# CEC1702 register map
Vendor: Microchip Technology; Series: CEC1702Q; File version: 0
CPU: CM4 r1p0, little endian, MPU, FPU, 3 interrupt priority bits, 155 interrupts
Registers are 32-bit, read-write, reset 0x0 unless marked. A register's access mark holds for its fields unless they carry their own. Offsets are from the block's base; [hi:lo] are bit positions; {n}, {i} and the like mark numbered series; 'fields as' and 'values as' point back to an identical list.

## QMSPI — The Quad SPI Master Controller may be used to communicate with various peripheral devices that use a Serial Peripheral Interface, such as EEPROMS, DACs and ADCs. The controller can be configured to support advanced SPI Flash devices with multi-phase access protocols.
Base 0x40005400; register names take the prefix QMSPI_
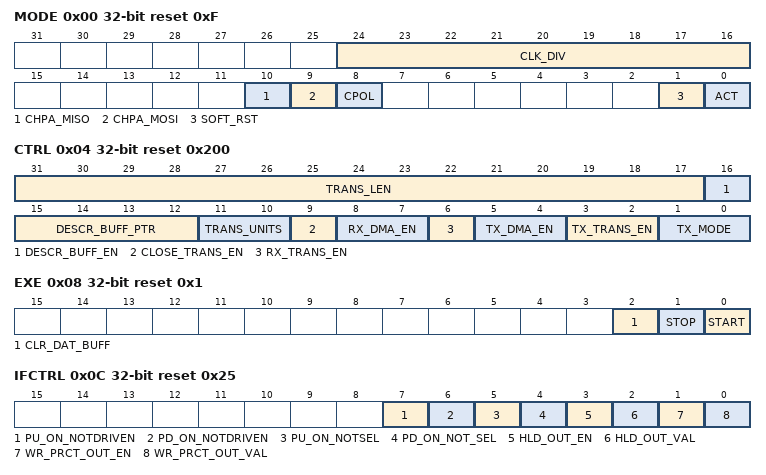
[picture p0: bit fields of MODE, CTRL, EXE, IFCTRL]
0x00 MODE reset 0xF — QMSPI Mode Register
  [24:16] CLK_DIV — The SPI clock divide in number of system clocks. A value of 1 divides the master clock by 1, a value of 255 divides the master clock by 255. A value of 0 divides the master clock by 256.
  [10] CHPA_MISO — Clock phase of the Master data in. Common SPI modes require this field to be programmed with the same value as CHPA_MOSI in this register. e.g. Mode 0: CPOL=0; CHPA_MISO=0; CHPA_MOSI=0; Mode 3: CPOL=1; CHPA_MISO=1; CHPA_MOSI=1. See datasheet for alternate mode settings. If CPOL=1: 1=Data are captured on the rising edge of the SPI clock; 0=Data are captured on the falling edge of the SPI clock. If CPOL=0: 1=Data are captured on the falling edge of the SPI clock; 0=Data are captured on the rising edge of the SPI clock
  [9] CHPA_MOSI — Clock phase of the Master data out. Common SPI modes require this field to be programmed with the same value as CHPA_MISO in this register. e.g. Mode 0: CPOL=0; CHPA_MISO=0; CHPA_MOSI=0; Mode 3: CPOL=1; CHPA_MISO=1; CHPA_MOSI=1. See datasheet for alternate mode settings. If CPOL=1: 1=Data changes on the falling edge of the SPI clock; 0=Data changes on the rising edge of the SPI clock. If CPOL=0: 1=Data changes on the rising edge of the SPI clock; 0=Data changes on the falling edge of the SPI clock
  [8] CPOL — Polarity of the SPI clock line when there are no transactions in process. 1=SPI Clock starts High; 0=SPI Clock starts Low.
  [1] SOFT_RST — Writing this bit with a 1 will reset the Quad SPI block. It is self-clearing.
  [0] ACT — This bit is used to activate the QMSPI block. 1=Enabled. The block is fully operational. 0=Disabled. Clocks are gated to conserve power and the output signals are set to their inactive state.
0x04 CTRL reset 0x200 — QMSPI SPI Control
  [31:17] TRANS_LEN — The length of the SPI transfer. The count is in bytes or bits, depending on the value of TRANS_LEN_BITS. A value of 0 means an infinite length transfer.
  [16] DESCR_BUFF_EN — This enables the Description Buffers to be used. 1=Description Buffers in use. The first buffer is defined in DESCRIPTION_BUFFER_POINTER. 0=Description Buffers disabled.
  [15:12] DESCR_BUFF_PTR — This field selects the first buffer used if Description Buffers are enabled.
  [11:10] TRANS_UNITS — 3=TRANSFER_LENGTH defined in units of 16-byte segments. 2=TRANSFER_LENGTH defined in units of 4-byte segments. 1=TRANSFER_LENGTH defined in units of bytes. 0=TRANSFER_LENGTH defined in units of bits.
  [9] CLOSE_TRANS_EN — This selects what action is taken at the end of a transfer. When the transaction closes, the Chip Select de-asserts, the SPI interface returns to IDLE and the DMA interface terminates When Description Buffers are in use this bit must be set only on the Last Buffer. 1=The transaction is terminated. 0=The transaction is not terminated
  [8:7] RX_DMA_EN — This bit enables DMA support for Receive Transfer. If enabled, DMA will be requested to empty the FIFO until either the interface reaches TRANSFER_LENGTH or the DMA sends a termination request. The size defined here must match DMA programmed access size. 1=DMA is enabled.and set to 1 Byte. 2=DMA is enabled and set to 2 Bytes. 3=DMA is enabled and set to 4 Bytes. 0=DMA is disabled. All data in the Receive Buffer must be emptied by firmware
  [6] RX_TRANS_EN — This bit enables the receive function of the SPI interface. 1=Receive is enabled. Data received from the SPI Slave is stored in the Receive Buffer. 0=Receive is disabled
  [5:4] TX_DMA_EN — This bit enables DMA support for Transmit Transfer. If enabled, DMA will be requested to fill the FIFO until either the interface reaches TRANSFER_LENGTH or the DMA sends a termination request. The size defined here must match DMA programmed access size. 1=DMA is enabled.and set to 1 Byte. 2=DMA is enabled and set to 2 Bytes. 3=DMA is enabled and set to 4 Bytes. 0=DMA is disabled. All data in the Transmit Buffer must be emptied by firmware
  [3:2] TX_TRANS_EN — This field bit selects the transmit function of the SPI interface. 3=Transmit Enabled in 1 Mode. The MOSI or IO Bus will send out only 1's. The Transmit Buffer will not be used. 2=Transmit Enabled in 0 Mode. The MOSI or IO Bus will send out only 0's. The Transmit Buffer will not be used. 1=Transmit Enabled. Data will be fetched from the Transmit Buffer and sent out on the MOSI or IO Bus. 0=Transmit is Disabled. Not data is sent. This will cause the MOSI be to be undriven, or the IO bus to be undriven if Receive is also disabled.
  [1:0] TX_MODE — This field sets the transmission mode. If this field is set for Dual Mode or Quad Mode then either. TX_TRANSFER_ENABLE or RX_TRANSFER_ENABLE must be 0. 3=Reserved; 2=Quad Mode; 1=Dual Mode; 0=Single/Duplex Mode.
0x08 EXE reset 0x1 — QMSPI Execute Register
  [2] CLR_DAT_BUFF — Writing a 1 to this bit will clear out the Transmit and Receive FIFOs. Any data stored in the FIFOs is discarded and all count fields are reset. Writing a 0 to this bit has no effect. This bit is self clearing.
  [1] STOP — Writing a 1 to this bit will stop any transfer in progress at the next byte boundary. Writing a 0 to this bit has no effect. This bit is self clearing. This bit must not be set to 1 if the field START in this register is set to 1.
  [0] START — Writing a 1 to this bit will start the SPI transfer. Writing a 0 to this bit has no effect. This bit is self-clearing. This bit must not be set to 1 if the field STOP in this register is set to 1.
0x0C IFCTRL reset 0x25 — QMSPI Interface Control Register
  [7] PU_ON_NOTDRIVEN — 1=Enable pull-up resistors on Transmit pins while the pins are not driven. 0=No pull-up resistors enabled ion Transmit pins.
  [6] PD_ON_NOTDRIVEN — 1=Enable pull-down resistors on Transmit pins while the pins are not driven. 0=No pull-down resistors enabled ion Transmit pins.
  [5] PU_ON_NOTSEL — 1=Enable pull-up resistors on Receive pins while the SPI Chip Select signal is not asserted. 0=No pull-up resistors enabled on Receive pins.
  [4] PD_ON_NOT_SEL — 1=Enable pull-down resistors on Receive pins while the SPI Chip Select signal is not asserted. 0=No pull-down resistors enabled on Receive pins
  [3] HLD_OUT_EN — 1=HOLD SPI Output Port is driven. 0=HOLD SPI Output Port is not driven.
  [2] HLD_OUT_VAL — This bit sets the value on the HOLD SPI Output Port if it is driven. 1=HOLD is driven to 1; 0=HOLD is driven to 0.
  [1] WR_PRCT_OUT_EN — 1=WRITE PROTECT SPI Output Port is driven. 0=WRITE PROTECT SPI Output Port is not driven
  [0] WR_PRCT_OUT_VAL — This bit sets the value on the WRITE PROTECT SPI Output Port if it is driven. 1=WRITE PROTECT is driven to 1; 0=WRITE PROTECT is driven to 0
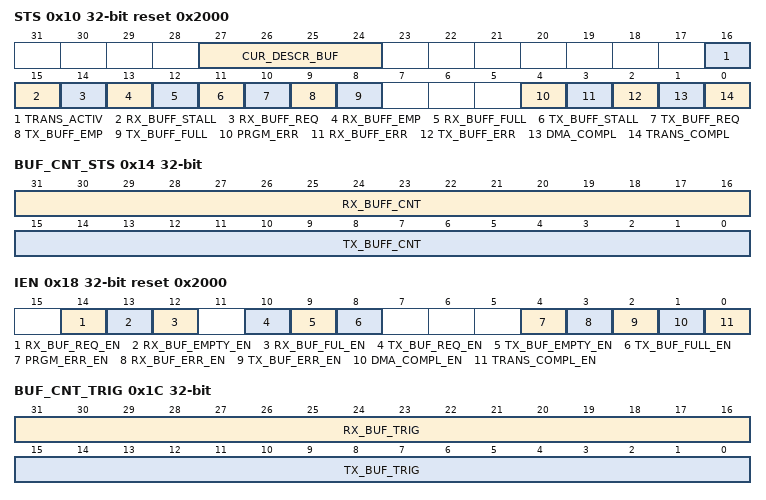
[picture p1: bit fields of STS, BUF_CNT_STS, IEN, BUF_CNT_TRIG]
0x10 STS reset 0x2000 — QMSPI Status Register
  [27:24] CUR_DESCR_BUF — This field shows the Description Buffer currently active. This field has no meaning if Description Buffers are not enabled.
  [16] TRANS_ACTIV — 1=A transfer is currently executing. 0=No transfer currently in progress.
  [15] RX_BUFF_STALL — 1=The SPI interface had been stalled due to a flow issue (an attempt by the interface to write to a full Receive Buffer). 0=No stalls occurred.
  [14] RX_BUFF_REQ — This status is asserted if the Receive Buffer reaches a high water mark established by the RECEIVE_BUFFER_TRIGGER field. 1=RECEIVE_BUFFER_COUNT is greater than or equal to RECEIVE_BUFFER_TRIGGER. 0=RECEIVE_BUFFER_COUNT is less than RECEIVE_BUFFER_TRIGGER.
  [13] RX_BUFF_EMP — 1=The Receive Buffer is empty. 0=The Receive Buffer is not empty.
  [12] RX_BUFF_FULL — 1=The Receive Buffer is full. 0=The Receive Buffer is not full.
  [11] TX_BUFF_STALL — 1=The SPI interface had been stalled due to a flow issue (an attempt by the interface to read from an empty Transmit Buffer). 0=No stalls occurred.
  [10] TX_BUFF_REQ — This status is asserted if the Transmit Buffer reaches a high water mark established by the TRANSMIT_BUFFER_TRIGGER field. 1=TRANSMIT_BUFFER_COUNT is less than or equal to TRANSMIT_BUFFER_TRIGGER; 0=TRANSMIT_BUFFER_COUNT is greater than TRANSMIT_BUFFER_TRIGGER.
  [9] TX_BUFF_EMP — 1=The Transmit Buffer is empty. 0=The Transmit Buffer is not empty.
  [8] TX_BUFF_FULL — 1=The Transmit Buffer is full. 0=The Transmit Buffer is not full.
  [4] PRGM_ERR — This bit if a programming error is detected. 1=Programming Error detected; 0=No programming error detected.
  [3] RX_BUFF_ERR — 1=Underflow error occurred (attempt to read from an empty Receive Buffer). 0=No underflow occurred.
  [2] TX_BUFF_ERR — 1=Overflow error occurred (attempt to write to a full Transmit Buffer). 0=No overflow occurred.
  [1] DMA_COMPL — This field has no meaning if DMA is not enabled. This bit will be set to 1 when the DMA controller asserts the DONE signal to the SPI controller. This occurs either when the SPI controller has closed the DMA transfer, or the DMA channel has completed its count. If both Transmit and Receive DMA transfers are active, then this bit will only assert after both have completed. If CLOSE_TRANSFER_ENABLE is enabled, DMA_COMPLETE and TRANSFER_COMPLETE will be asserted simultaneously. This status is not inhibited by the description buffers, so it can fire on all valid description buffers while operating in that mode. 1=DMA completed; 0=DMA not completed.
  [0] TRANS_COMPL — In Manual Mode (neither DMA nor Description Buffers are enabled), this bit will be set to 1 when the transfer matches TRANSFER_LENGTH. If DMA Mode is enabled, this bit will be set to 1 when DMA_COMPLETE is set to 1. In Description Buffer Mode, this bit will be set to 1 only when the Last Buffer completes its transfer. In all cases, this bit will be set to 1 if the STOP bit is set to 1 and the controller has completed the current 8 bits being copied. 1=Transfer completed; 0=Transfer not complete.
0x14 BUF_CNT_STS — QMSPI Buffer Count Status Register
  [31:16] RX_BUFF_CNT — This is a count of the number of bytes currently valid in the Receive Buffer.
  [15:0] TX_BUFF_CNT — This is a count of the number of bytes currently valid in the Transmit Buffer.
0x18 IEN reset 0x2000 — QMSPI Interrupt Enable Register
  [14] RX_BUF_REQ_EN — 1=Enable an interrupt if RECEIVE_BUFFER_REQUEST is asserted. 0=Disable the interrupt.
  [13] RX_BUF_EMPTY_EN — 1=Enable an interrupt if RECEIVE_BUFFER_EMPTY is asserted. 0=Disable the interrupt.
  [12] RX_BUF_FUL_EN — 1=Enable an interrupt if RECEIVE_BUFFER_FULL is asserted. 0=Disable the interrupt.
  [10] TX_BUF_REQ_EN — 1=Enable an interrupt if TRANSMIT_BUFFER_REQUEST is asserted. 0=Disable the interrupt.
  [9] TX_BUF_EMPTY_EN — 1=Enable an interrupt if TRANSMIT_BUFFER_EMPTY is asserted. 0=Disable the interrupt.
  [8] TX_BUF_FULL_EN — 1=Enable an interrupt if TRANSMIT_BUFFER_FULL is asserted. 0=Disable the interrupt.
  [4] PRGM_ERR_EN — 1=Enable an interrupt if PROGRAMMING_ERROR is asserted. 0=Disable the interrupt.
  [3] RX_BUF_ERR_EN — 1=Enable an interrupt if RECEIVE_BUFFER_ERROR is asserted. 0=Disable the interrupt.
  [2] TX_BUF_ERR_EN — 1=Enable an interrupt if TRANSMIT_BUFFER_ERROR is asserted. 0=Disable the interrupt.
  [1] DMA_COMPL_EN — 1=Enable an interrupt if DMA_COMPLETE is asserted. 0=Disable the interrupt.
  [0] TRANS_COMPL_EN — 1=Enable an interrupt if TRANSFER_COMPLETE is asserted. 0=Disable the interrupt.
0x1C BUF_CNT_TRIG — QMSPI Buffer Count Trigger Register
  [31:16] RX_BUF_TRIG — An interrupt is triggered if the RECEIVE_BUFFER_COUNT field is greater than or equal to this value. A value of 0 disables the interrupt.
  [15:0] TX_BUF_TRIG — An interrupt is triggered if the TRANSMIT_BUFFER_COUNT field is less than or equal to this value. A value of 0 disables the interrupt.
0x20 TX_FIFO_u32 — QMSPI Transmit Buffer Register
  [31:0] TX_BUF — Writes to this register store data to be transmitted from the SPI Master to the external SPI Slave. Writes to this block will be written to the Transmit FIFO. A 1 Byte write fills 1 byte of the FIFO. A Word write fills 2 Bytes and a Doubleword write fills 4 bytes. The data must always be aligned to the bottom most byte (so 1 byte write is on bits [7:0] and Word write is on [15:0]). An overflow condition, TRANSMIT_BUFFER_ERROR, if a write to a full FIFO occurs. Write accesses to this register increment the TRANSMIT_BUFFER_COUNT field.
{0x20+2i} TX_FIFO_u16[{i}] (i=0..1) 16-bit — QMSPI Transmit Buffer Register
  fields as TX_FIFO_u32
{0x20+i} TX_FIFO_u08[{i}] (i=0..3) 8-bit — QMSPI Transmit Buffer Register
  fields as TX_FIFO_u32
0x24 RX_FIFO_u32 — QMSPI Receive Buffer Register
  [31:0] RX_BUF — Buffer that stores data from the external SPI Slave device to the SPI Master (this block), which is received over MISO or IO. Reads from this register will empty the Rx FIFO. A 1 Byte read will have valid data on bits [7:0] and a Word read will have data on bits [15:0]. It is possible to request more data than the FIFO has (underflow condition), but this will cause an error (Rx Buffer Error). Read accesses to this register decrement the RECEIVE_BUFFER_COUNT field.
{0x24+2i} RX_FIFO_u16[{i}] (i=0..1) 16-bit — QMSPI Receive Buffer Register
  fields as RX_FIFO_u32
{0x24+i} RX_FIFO_u08[{i}] (i=0..3) 8-bit — QMSPI Receive Buffer Register
  fields as RX_FIFO_u32
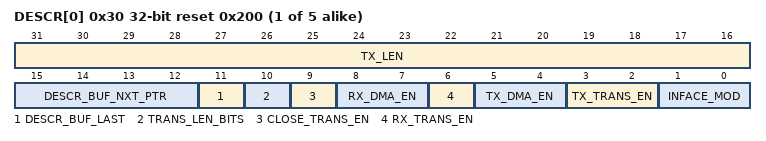
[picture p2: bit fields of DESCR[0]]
{0x30+4i} DESCR[{i}] (i=0..4) reset 0x200 — QMSPI Description Buffer Register
  [31:16] TX_LEN — The length of the SPI transfer. The count is in bytes or bits, depending on the value of TX_LEN_BITS. A value of 0 means an infinite length transfer.
  [15:12] DESCR_BUF_NXT_PTR — This defines the next buffer to be used if Description Buffers are enabled and this is not the last buffer. This can point to the current buffer, creating an infinite loop.
  [11] DESCR_BUF_LAST — If this bit is 1 then this is the last Description Buffer in the chain. When the transfer described by this buffer completes the TRANSFER_ COMPLETE status will be set to 1. If this bit is 0, then this is not the last buffer in use. When the transfer completes the next buffer will be activated, and no additional status will be asserted.
  [10] TRANS_LEN_BITS — 1=TRANSFER_LENGTH defined in bits. 0=TRANSFER_LENGTH defined in bytes
  [9] CLOSE_TRANS_EN — This selects what action is taken at the end of a transfer. This bit must be set only on the Last Buffer. 1=The transfer is terminated. The Chip Select de-asserts, the SPI interface returns to IDLE and the DMA interface completes the transfer. 0=The transfer is not closed. Chip Select remains asserted and the DMA interface and the SPI interface remain active
  [8:7] RX_DMA_EN — This bit enables DMA support for Receive Transfer. If enabled, DMA will be requested to empty the FIFO until either the interface reaches TRANSFER_LENGTH or the DMA sends a termination request. The size defined here must match DMA programmed access size. 1=DMA is enabled.and set to 1 Byte. 2=DMA is enabled and set to 2 Bytes. 3=DMA is enabled and set to 4 Bytes. 0=DMA is disabled. All data in the Receive Buffer must be emptied by firmware.
  [6] RX_TRANS_EN — This bit enables the receive function of the SPI interface. 1=Receive is enabled. Data received from the SPI Slave is stored in the Receive Buffer; 0=Receive is disabled.
  [5:4] TX_DMA_EN — This bit enables DMA support for Transmit Transfer. If enabled, DMA will be requested to fill the FIFO until either the interface reaches TRANSFER_LENGTH or the DMA sends a termination request. The size defined here must match DMA programmed access size. 1=DMA is enabled.and set to 1 Byte. 2=DMA is enabled and set to 2 Bytes. 3=DMA is enabled and set to 4 Bytes 0=DMA is disabled. All data in the Transmit Buffer must be emptied by firmware.
  [3:2] TX_TRANS_EN — This field bit selects the transmit function of the SPI interface. 3=Transmit Enabled in 1 Mode. The MOSI or IO Bus will send out only 1's. The Transmit Buffer will not be used. 2=Transmit Enabled in 0 Mode. The MOSI or IO Bus will send out only 0's. The Transmit Buffer will not be used. 1=Transmit Enabled. Data will be fetched from the Transmit Buffer and sent out on the MOSI or IO Bus. 0=Transmit is Disabled. No data is sent. This will cause the MOSI be to be undriven, or the IO bus to be undriven if Receive is also disabled.
  [1:0] INFACE_MOD — This field sets the transmission mode. If this field is set for Dual Mode or Quad Mode then either TX_TRANSFER_ENABLE or RX_TRANSFER_ENABLE must be 0.3=Reserved; 2=Quad Mode; 1=Dual Mode; 0=Single/Duplex Mode.
